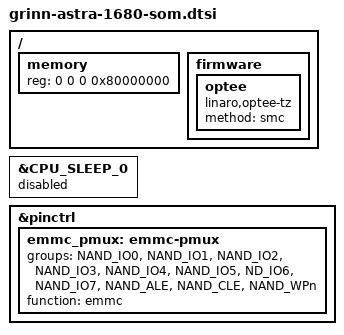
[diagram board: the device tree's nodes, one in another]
// SPDX-License-Identifier: (GPL-2.0-only OR MIT)
/*
 * Copyright (C) 2026 Grinn sp. z o.o.
 */

#include "dolphin.dtsi"

/ {
	memory {
		device_type = "memory";
		reg = <0 0 0 0x80000000>;
	};

	firmware {
		optee {
			compatible = "linaro,optee-tz";
			method = "smc";
		};
	};
};

&CPU_SLEEP_0 {
	status = "disabled";
};

&pinctrl {
	emmc_pmux: emmc-pmux {
		groups = "NAND_IO0", "NAND_IO1", "NAND_IO2", "NAND_IO3", "NAND_IO4", "NAND_IO5", "ND_IO6", "NAND_IO7", "NAND_ALE", "NAND_CLE", "NAND_WPn";
		function = "emmc";
	};
};
